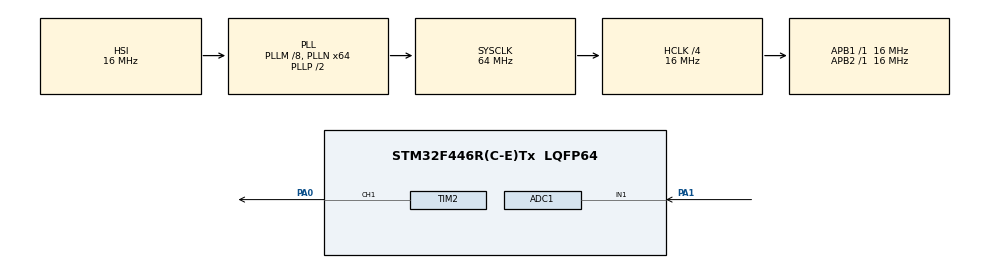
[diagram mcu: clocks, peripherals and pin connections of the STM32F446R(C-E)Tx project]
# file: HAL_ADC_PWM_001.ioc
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ADC1.Channel-0\#ChannelRegularConversion=ADC_CHANNEL_1
ADC1.ContinuousConvMode=ENABLE
ADC1.NbrOfConversionFlag=1
ADC1.Rank-0\#ChannelRegularConversion=1
ADC1.SamplingTime-0\#ChannelRegularConversion=ADC_SAMPLETIME_144CYCLES
ADC1.master=1
Mcu.Family=STM32F4
Mcu.Name=STM32F446R(C-E)Tx
Mcu.Package=LQFP64
NVIC.PriorityGroup=NVIC_PRIORITYGROUP_4
PA0-WKUP.Signal=S_TIM2_CH1_ETR
PA1.Signal=ADCx_IN1
PC14-OSC32_IN.Mode=LSE-External-Oscillator
PC14-OSC32_IN.Signal=RCC_OSC32_IN
PC15-OSC32_OUT.Mode=LSE-External-Oscillator
PC15-OSC32_OUT.Signal=RCC_OSC32_OUT
ProjectManager.HeapSize=0x200
ProjectManager.StackSize=0x400
ProjectManager.TargetToolchain=MDK-ARM V5
RCC.AHBCLKDivider=RCC_SYSCLK_DIV4
RCC.AHBFreq_Value=16000000
RCC.APB1Freq_Value=16000000
RCC.APB1TimFreq_Value=16000000
RCC.APB2Freq_Value=16000000
RCC.APB2TimFreq_Value=16000000
RCC.CortexFreq_Value=16000000
RCC.HCLKFreq_Value=16000000
RCC.PLLM=8
RCC.PLLN=64
RCC.SYSCLKFreq_VALUE=64000000
RCC.SYSCLKSource=RCC_SYSCLKSOURCE_PLLCLK
RCC.USBFreq_Value=64000000
RCC.VCOOutputFreq_Value=128000000
SH.ADCx_IN1.0=ADC1_IN1,IN1
SH.S_TIM2_CH1_ETR.0=TIM2_CH1,PWM Generation1 CH1
TIM2.Channel-PWM\ Generation1\ CH1=TIM_CHANNEL_1
TIM2.OC1Preload_PWM=ENABLE
TIM2.Period=4095
TIM2.Prescaler=24
VP_TIM2_VS_ClockSourceINT.Mode=Internal
board=custom

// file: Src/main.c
/* USER CODE BEGIN Header */
/**
  ******************************************************************************
  * @file           : main.c
  * @brief          : Main program body
  ******************************************************************************
  * @attention
  *
  * <h2><center>&copy; Copyright (c) 2020 STMicroelectronics.
  * All rights reserved.</center></h2>
  *
  * This software component is licensed by ST under BSD 3-Clause license,
  * the "License"; You may not use this file except in compliance with the
  * License. You may obtain a copy of the License at:
  *                        opensource.org/licenses/BSD-3-Clause
  *
  ******************************************************************************
  */
/* USER CODE END Header */

#include "main.h"

ADC_HandleTypeDef hadc1;

TIM_HandleTypeDef htim2;

/* USER CODE BEGIN PV */
	uint16_t	ADC_DATA	=	0	,pulse	;
/* USER CODE END PV */

void SystemClock_Config(void);
static void MX_GPIO_Init(void);
static void MX_ADC1_Init(void);
static void MX_TIM2_Init(void);
/* USER CODE BEGIN PFP */
	void	READ_ADC()
	{
		if(HAL_ADC_PollForConversion(&hadc1,1000000)	==	HAL_OK	)
		{
				ADC_DATA	=	HAL_ADC_GetValue(&hadc1)	;

				pulse	=	ADC_DATA	;

		}

	}
/* USER CODE END PFP */

int main(void)
{

  /* MCU Configuration--------------------------------------------------------*/

  /* Reset of all peripherals, Initializes the Flash interface and the Systick. */
  HAL_Init();

  /* Configure the system clock */
  SystemClock_Config();

  /* Initialize all configured peripherals */
  MX_GPIO_Init();
  MX_ADC1_Init();
  MX_TIM2_Init();
  /* USER CODE BEGIN 2 */
	HAL_ADC_Start(&hadc1)	;
	HAL_TIM_PWM_Start(&htim2,TIM_CHANNEL_1);
  /* USER CODE END 2 */

  /* Infinite loop */
  /* USER CODE BEGIN WHILE */
  while (1)
  {
			READ_ADC()	;

			__HAL_TIM_SetCompare(&htim2,TIM_CHANNEL_1,pulse)	;

    /* USER CODE END WHILE */

  }
}

void SystemClock_Config(void)
{
  RCC_OscInitTypeDef RCC_OscInitStruct = {0};
  RCC_ClkInitTypeDef RCC_ClkInitStruct = {0};

  /** Configure the main internal regulator output voltage
  */
  __HAL_RCC_PWR_CLK_ENABLE();
  __HAL_PWR_VOLTAGESCALING_CONFIG(PWR_REGULATOR_VOLTAGE_SCALE3);
  /** Initializes the CPU, AHB and APB busses clocks
  */
  RCC_OscInitStruct.OscillatorType = RCC_OSCILLATORTYPE_HSI;
  RCC_OscInitStruct.HSIState = RCC_HSI_ON;
  RCC_OscInitStruct.HSICalibrationValue = RCC_HSICALIBRATION_DEFAULT;
  RCC_OscInitStruct.PLL.PLLState = RCC_PLL_ON;
  RCC_OscInitStruct.PLL.PLLSource = RCC_PLLSOURCE_HSI;
  RCC_OscInitStruct.PLL.PLLM = 8;
  RCC_OscInitStruct.PLL.PLLN = 64;
  RCC_OscInitStruct.PLL.PLLP = RCC_PLLP_DIV2;
  RCC_OscInitStruct.PLL.PLLQ = 2;
  RCC_OscInitStruct.PLL.PLLR = 2;
  if (HAL_RCC_OscConfig(&RCC_OscInitStruct) != HAL_OK)
  {
    Error_Handler();
  }
  /** Initializes the CPU, AHB and APB busses clocks
  */
  RCC_ClkInitStruct.ClockType = RCC_CLOCKTYPE_HCLK|RCC_CLOCKTYPE_SYSCLK
                              |RCC_CLOCKTYPE_PCLK1|RCC_CLOCKTYPE_PCLK2;
  RCC_ClkInitStruct.SYSCLKSource = RCC_SYSCLKSOURCE_PLLCLK;
  RCC_ClkInitStruct.AHBCLKDivider = RCC_SYSCLK_DIV4;
  RCC_ClkInitStruct.APB1CLKDivider = RCC_HCLK_DIV1;
  RCC_ClkInitStruct.APB2CLKDivider = RCC_HCLK_DIV1;

  if (HAL_RCC_ClockConfig(&RCC_ClkInitStruct, FLASH_LATENCY_0) != HAL_OK)
  {
    Error_Handler();
  }
}

static void MX_ADC1_Init(void)
{

  ADC_ChannelConfTypeDef sConfig = {0};

  /** Configure the global features of the ADC (Clock, Resolution, Data Alignment and number of conversion)
  */
  hadc1.Instance = ADC1;
  hadc1.Init.ClockPrescaler = ADC_CLOCK_SYNC_PCLK_DIV2;
  hadc1.Init.Resolution = ADC_RESOLUTION_12B;
  hadc1.Init.ScanConvMode = DISABLE;
  hadc1.Init.ContinuousConvMode = ENABLE;
  hadc1.Init.DiscontinuousConvMode = DISABLE;
  hadc1.Init.ExternalTrigConvEdge = ADC_EXTERNALTRIGCONVEDGE_NONE;
  hadc1.Init.ExternalTrigConv = ADC_SOFTWARE_START;
  hadc1.Init.DataAlign = ADC_DATAALIGN_RIGHT;
  hadc1.Init.NbrOfConversion = 1;
  hadc1.Init.DMAContinuousRequests = DISABLE;
  hadc1.Init.EOCSelection = ADC_EOC_SINGLE_CONV;
  if (HAL_ADC_Init(&hadc1) != HAL_OK)
  {
    Error_Handler();
  }
  /** Configure for the selected ADC regular channel its corresponding rank in the sequencer and its sample time.
  */
  sConfig.Channel = ADC_CHANNEL_1;
  sConfig.Rank = 1;
  sConfig.SamplingTime = ADC_SAMPLETIME_144CYCLES;
  if (HAL_ADC_ConfigChannel(&hadc1, &sConfig) != HAL_OK)
  {
    Error_Handler();
  }

}

static void MX_TIM2_Init(void)
{

  TIM_ClockConfigTypeDef sClockSourceConfig = {0};
  TIM_MasterConfigTypeDef sMasterConfig = {0};
  TIM_OC_InitTypeDef sConfigOC = {0};

  htim2.Instance = TIM2;
  htim2.Init.Prescaler = 24;
  htim2.Init.CounterMode = TIM_COUNTERMODE_UP;
  htim2.Init.Period = 4095;
  htim2.Init.ClockDivision = TIM_CLOCKDIVISION_DIV1;
  htim2.Init.AutoReloadPreload = TIM_AUTORELOAD_PRELOAD_DISABLE;
  if (HAL_TIM_Base_Init(&htim2) != HAL_OK)
  {
    Error_Handler();
  }
  sClockSourceConfig.ClockSource = TIM_CLOCKSOURCE_INTERNAL;
  if (HAL_TIM_ConfigClockSource(&htim2, &sClockSourceConfig) != HAL_OK)
  {
    Error_Handler();
  }
  if (HAL_TIM_PWM_Init(&htim2) != HAL_OK)
  {
    Error_Handler();
  }
  sMasterConfig.MasterOutputTrigger = TIM_TRGO_RESET;
  sMasterConfig.MasterSlaveMode = TIM_MASTERSLAVEMODE_DISABLE;
  if (HAL_TIMEx_MasterConfigSynchronization(&htim2, &sMasterConfig) != HAL_OK)
  {
    Error_Handler();
  }
  sConfigOC.OCMode = TIM_OCMODE_PWM1;
  sConfigOC.Pulse = 0;
  sConfigOC.OCPolarity = TIM_OCPOLARITY_HIGH;
  sConfigOC.OCFastMode = TIM_OCFAST_DISABLE;
  if (HAL_TIM_PWM_ConfigChannel(&htim2, &sConfigOC, TIM_CHANNEL_1) != HAL_OK)
  {
    Error_Handler();
  }
  HAL_TIM_MspPostInit(&htim2);

}

static void MX_GPIO_Init(void)
{

  /* GPIO Ports Clock Enable */
  __HAL_RCC_GPIOC_CLK_ENABLE();
  __HAL_RCC_GPIOA_CLK_ENABLE();

}

void Error_Handler(void)
{
}

/************************ (C) COPYRIGHT STMicroelectronics *****END OF FILE****/
